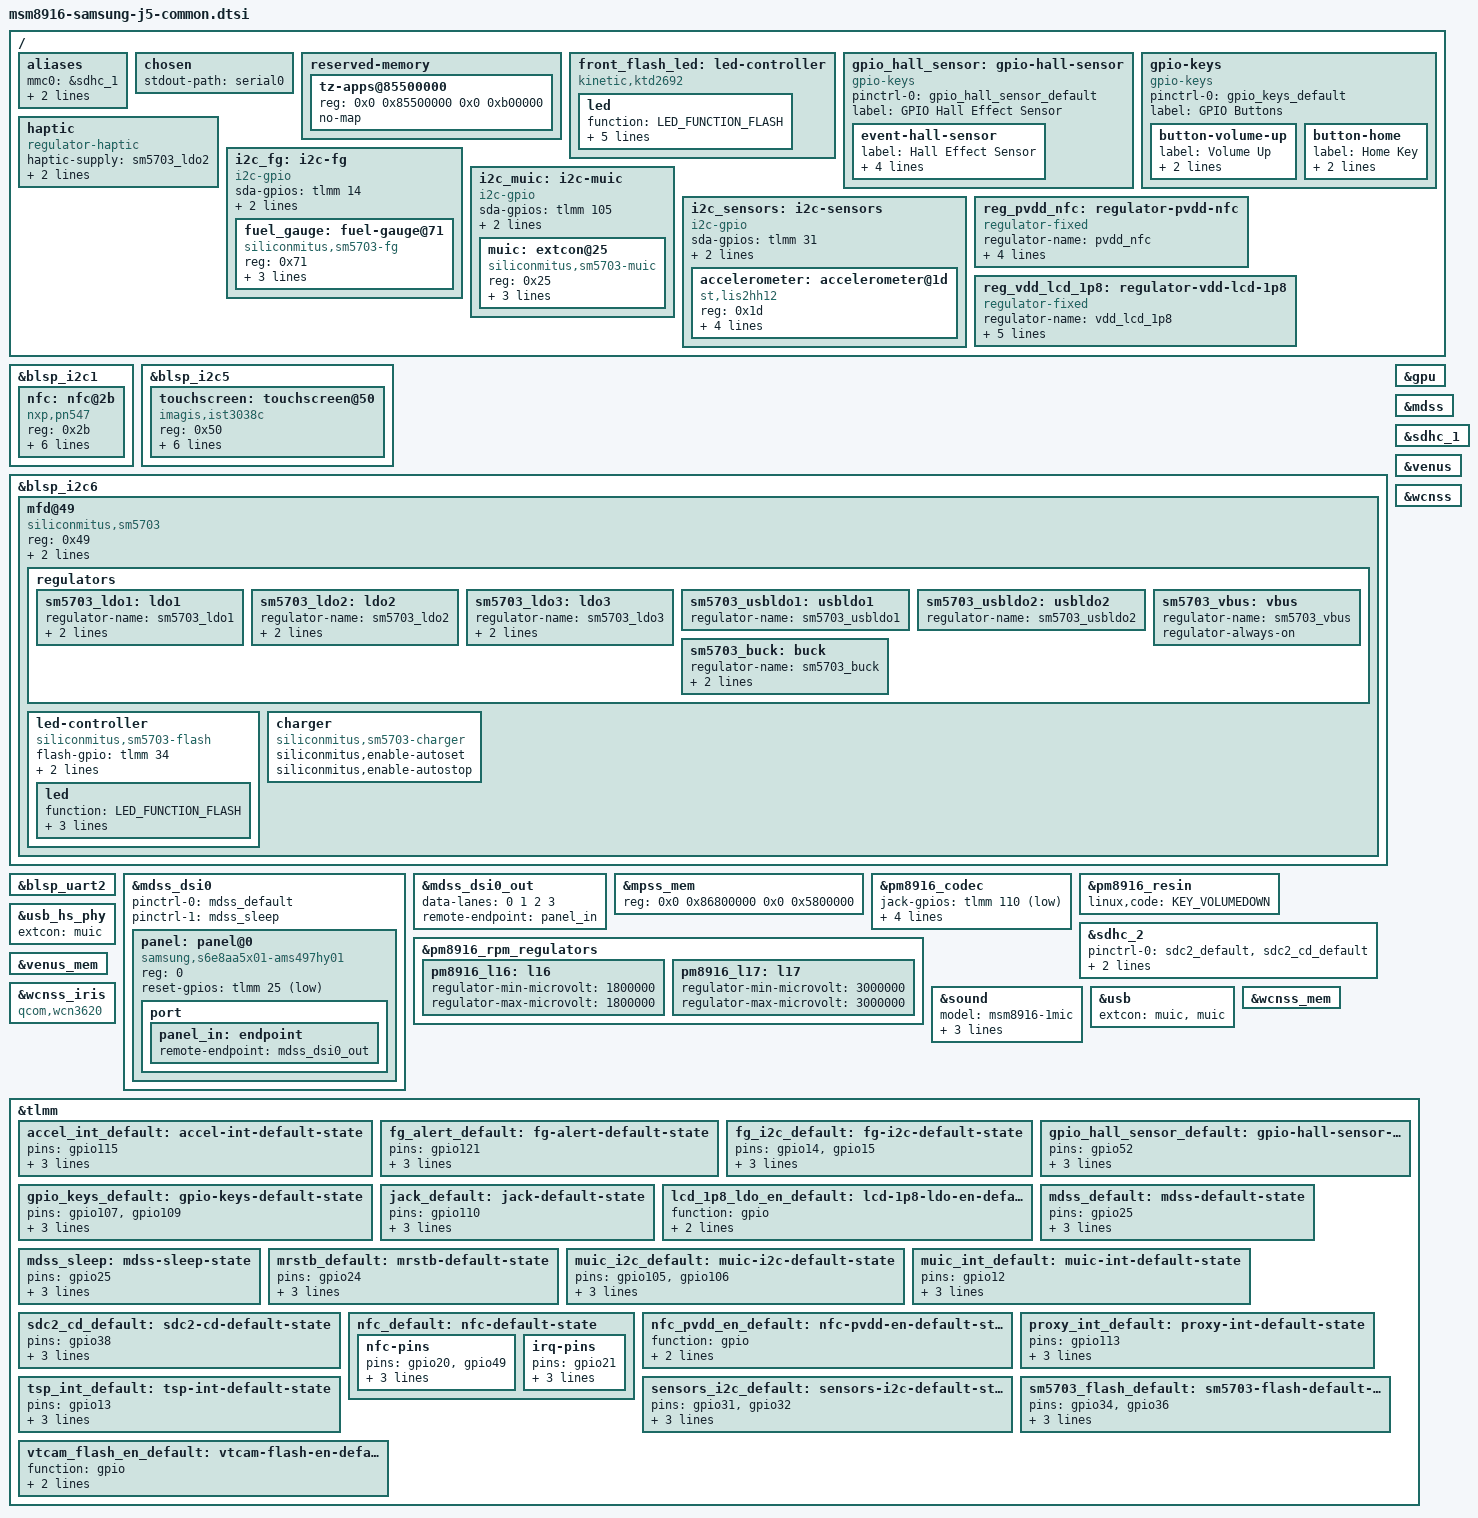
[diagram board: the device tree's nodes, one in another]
// SPDX-License-Identifier: GPL-2.0-only

#include "msm8916-pm8916.dtsi"
#include "msm8916-modem-qdsp6.dtsi"

#include <dt-bindings/gpio/gpio.h>
#include <dt-bindings/input/input.h>
#include <dt-bindings/interrupt-controller/irq.h>
#include <dt-bindings/leds/common.h>

/ {
	aliases {
		mmc0 = &sdhc_1; /* eMMC */
		mmc1 = &sdhc_2; /* SD card */
		serial0 = &blsp_uart2;
	};

	chosen {
		stdout-path = "serial0";
	};

	reserved-memory {
		/* Additional memory used by Samsung firmware modifications */
		tz-apps@85500000 {
			reg = <0x0 0x85500000 0x0 0xb00000>;
			no-map;
		};
	};

	front_flash_led: led-controller {
		compatible = "kinetic,ktd2692";

		led {
			function = LED_FUNCTION_FLASH;
			color = <LED_COLOR_ID_WHITE>;

			led-max-microamp = <300000>;
			flash-max-microamp = <1500000>;
			flash-max-timeout-us = <1835000>;

			pinctrl-0 = <&vtcam_flash_en_default>;
			pinctrl-names = "default";
		};
	};

	gpio_hall_sensor: gpio-hall-sensor {
		compatible = "gpio-keys";

		pinctrl-names = "default";
		pinctrl-0 = <&gpio_hall_sensor_default>;

		label = "GPIO Hall Effect Sensor";

		event-hall-sensor {
			label = "Hall Effect Sensor";
			gpios = <&tlmm 52 GPIO_ACTIVE_LOW>;
			linux,input-type = <EV_SW>;
			linux,code = <SW_LID>;
			linux,can-disable;
		};
	};

	gpio-keys {
		compatible = "gpio-keys";

		pinctrl-names = "default";
		pinctrl-0 = <&gpio_keys_default>;

		label = "GPIO Buttons";

		button-volume-up {
			label = "Volume Up";
			gpios = <&tlmm 107 GPIO_ACTIVE_LOW>;
			linux,code = <KEY_VOLUMEUP>;
		};

		button-home {
			label = "Home Key";
			gpios = <&tlmm 109 GPIO_ACTIVE_LOW>;
			linux,code = <KEY_HOMEPAGE>;
		};
	};

	haptic {
		compatible = "regulator-haptic";
		haptic-supply = <&sm5703_ldo2>;
		min-microvolt = <3300000>;
		max-microvolt = <3300000>;
	};

	i2c_fg: i2c-fg {
		compatible = "i2c-gpio";

		/* I2C4 */
		sda-gpios = <&tlmm 14 (GPIO_ACTIVE_HIGH|GPIO_OPEN_DRAIN)>;
		scl-gpios = <&tlmm 15 (GPIO_ACTIVE_HIGH|GPIO_OPEN_DRAIN)>;

		pinctrl-0 = <&fg_i2c_default>;
		pinctrl-names = "default";

		#address-cells = <1>;
		#size-cells = <0>;

		fuel_gauge: fuel-gauge@71 {
			compatible = "siliconmitus,sm5703-fg";
			reg = <0x71>;

			interrupt-parent = <&tlmm>;
			interrupts = <121 IRQ_TYPE_EDGE_FALLING>;

			pinctrl-0 = <&fg_alert_default>;
			pinctrl-names = "default";
		};
	};

	i2c_muic: i2c-muic {
		compatible = "i2c-gpio";
		sda-gpios = <&tlmm 105 (GPIO_ACTIVE_HIGH|GPIO_OPEN_DRAIN)>;
		scl-gpios = <&tlmm 106 (GPIO_ACTIVE_HIGH|GPIO_OPEN_DRAIN)>;

		pinctrl-names = "default";
		pinctrl-0 = <&muic_i2c_default>;

		#address-cells = <1>;
		#size-cells = <0>;

		muic: extcon@25 {
			compatible = "siliconmitus,sm5703-muic";
			reg = <0x25>;

			interrupt-parent = <&tlmm>;
			interrupts = <12 IRQ_TYPE_EDGE_FALLING>;

			pinctrl-names = "default";
			pinctrl-0 = <&muic_int_default>;
		};
	};

	i2c_sensors: i2c-sensors {
		compatible = "i2c-gpio";

		sda-gpios = <&tlmm 31 (GPIO_ACTIVE_HIGH|GPIO_OPEN_DRAIN)>;
		scl-gpios = <&tlmm 32 (GPIO_ACTIVE_HIGH|GPIO_OPEN_DRAIN)>;

		pinctrl-0 = <&sensors_i2c_default>;
		pinctrl-names = "default";

		#address-cells = <1>;
		#size-cells = <0>;

		accelerometer: accelerometer@1d {
			compatible = "st,lis2hh12";
			reg = <0x1d>;

			interrupts-extended = <&tlmm 115 IRQ_TYPE_LEVEL_HIGH>;

			pinctrl-0 = <&accel_int_default>;
			pinctrl-names = "default";

			st,drdy-int-pin = <1>;
		};
	};

	reg_pvdd_nfc: regulator-pvdd-nfc {
		compatible = "regulator-fixed";
		regulator-name = "pvdd_nfc";
		regulator-min-microvolt = <1800000>;
		regulator-max-microvolt = <1800000>;

		enable-active-high;

		pinctrl-0 = <&nfc_pvdd_en_default>;
		pinctrl-names = "default";
	};

	reg_vdd_lcd_1p8: regulator-vdd-lcd-1p8 {
		compatible = "regulator-fixed";
		regulator-name = "vdd_lcd_1p8";
		regulator-min-microvolt = <1800000>;
		regulator-max-microvolt = <1800000>;
		vin-supply = <&pm8916_s4>;

		enable-active-high;

		pinctrl-0 = <&lcd_1p8_ldo_en_default>;
		pinctrl-names = "default";
	};
};

&blsp_i2c1 {
	status = "okay";

	nfc: nfc@2b {
		compatible = "nxp,pn547", "nxp,nxp-nci-i2c";
		reg = <0x2b>;

		interrupt-parent = <&tlmm>;
		interrupts = <21 IRQ_TYPE_EDGE_RISING>;

		enable-gpios = <&tlmm 20 GPIO_ACTIVE_HIGH>;
		firmware-gpios = <&tlmm 49 GPIO_ACTIVE_HIGH>;

		pinctrl-0 = <&nfc_default>;
		pinctrl-names = "default";

		pvdd-supply = <&reg_pvdd_nfc>;
	};
};

&blsp_i2c5 {
	status = "okay";

	touchscreen: touchscreen@50 {
		compatible = "imagis,ist3038c";
		reg = <0x50>;

		interrupt-parent = <&tlmm>;
		interrupts = <13 IRQ_TYPE_EDGE_FALLING>;

		touchscreen-size-x = <720>;
		touchscreen-size-y = <1280>;

		vddio-supply = <&pm8916_l6>;

		pinctrl-0 = <&tsp_int_default>;
		pinctrl-names = "default";
	};
};

&blsp_i2c6 {
	status = "okay";

	mfd@49 {
		compatible = "siliconmitus,sm5703";
		reg = <0x49>;

		reset-gpio = <&tlmm 24 GPIO_ACTIVE_HIGH>;

		pinctrl-0 = <&mrstb_default>;
		pinctrl-names = "default";

		regulators {
			sm5703_ldo1: ldo1 {
				regulator-name = "sm5703_ldo1";
				regulator-min-microvolt = <2800000>;
				regulator-max-microvolt = <2800000>;
			};

			sm5703_ldo2: ldo2 {
				regulator-name = "sm5703_ldo2";
				regulator-min-microvolt = <1500000>;
				regulator-max-microvolt = <3300000>;
			};

			sm5703_ldo3: ldo3 {
				regulator-name = "sm5703_ldo3";
				regulator-min-microvolt = <3300000>;
				regulator-max-microvolt = <3300000>;
			};

			sm5703_usbldo1: usbldo1 {
				regulator-name = "sm5703_usbldo1";
			};

			sm5703_usbldo2: usbldo2 {
				regulator-name = "sm5703_usbldo2";
			};

			sm5703_vbus: vbus {
				regulator-name = "sm5703_vbus";
				/* HACK Keep it always on otherwise the USB
				 * network breaks */
				regulator-always-on;
			};

			sm5703_buck: buck {
				regulator-name = "sm5703_buck";
				regulator-min-microvolt = <1500000>;
				regulator-max-microvolt = <1500000>;
			};
		};

		led-controller {
			compatible = "siliconmitus,sm5703-flash";

			flash-gpio = <&tlmm 34 GPIO_ACTIVE_HIGH>;
			torch-gpio = <&tlmm 36 GPIO_ACTIVE_HIGH>;

			pinctrl-0 = <&sm5703_flash_default>;
			pinctrl-names = "default";

			led {
				function = LED_FUNCTION_FLASH;
				color = <LED_COLOR_ID_WHITE>;
				led-max-microamp = <170000>;
				flash-max-microamp = <1200000>;
			};
		};

		charger {
			compatible = "siliconmitus,sm5703-charger";
			siliconmitus,enable-autoset;
			siliconmitus,enable-autostop;
		};
	};
};

&blsp_uart2 {
	status = "okay";
};

&gpu {
	status = "okay";
};

&mdss {
	status = "okay";
};

&mdss_dsi0 {
	pinctrl-0 = <&mdss_default>;
	pinctrl-1 = <&mdss_sleep>;
	pinctrl-names = "default", "sleep";

	panel: panel@0 {
		reg = <0>;

		compatible = "samsung,s6e8aa5x01-ams497hy01";

		reset-gpios = <&tlmm 25 GPIO_ACTIVE_LOW>;

		port {
			panel_in: endpoint {
				remote-endpoint = <&mdss_dsi0_out>;
			};
		};
	};
};

&mdss_dsi0_out {
	data-lanes = <0 1 2 3>;
	remote-endpoint = <&panel_in>;
};

&mpss_mem {
	reg = <0x0 0x86800000 0x0 0x5800000>;
};

&pm8916_codec {
	jack-gpios = <&tlmm 110 GPIO_ACTIVE_LOW>;
	qcom,micbias-lvl = <2800>;
	qcom,mbhc-vthreshold-low = <75 150 237 450 500>;
	qcom,mbhc-vthreshold-high = <75 150 237 450 500>;

	pinctrl-0 = <&jack_default>;
	pinctrl-names = "default";
};

&pm8916_resin {
	status = "okay";
	linux,code = <KEY_VOLUMEDOWN>;
};

&pm8916_rpm_regulators {
	pm8916_l16: l16 {
		regulator-min-microvolt = <1800000>;
		regulator-max-microvolt = <1800000>;
	};

	pm8916_l17: l17 {
		regulator-min-microvolt = <3000000>;
		regulator-max-microvolt = <3000000>;
	};
};

&sdhc_1 {
	status = "okay";
};

&sdhc_2 {
	status = "okay";

	pinctrl-names = "default", "sleep";
	pinctrl-0 = <&sdc2_default &sdc2_cd_default>;
	pinctrl-1 = <&sdc2_sleep &sdc2_cd_default>;

	cd-gpios = <&tlmm 38 GPIO_ACTIVE_LOW>;
};

&sound {
	model = "msm8916-1mic";
	audio-routing =
		"AMIC1", "MIC BIAS External1",
		"AMIC2", "MIC BIAS Internal2",
		"AMIC3", "MIC BIAS External1";
};

&usb {
	extcon = <&muic>, <&muic>;
	//vbus-supply = <&sm5703_vbus>;
	status = "okay";
};

&usb_hs_phy {
	extcon = <&muic>;
};

&venus {
	status = "okay";
};

&venus_mem {
	status = "okay";
};

&wcnss {
	status = "okay";
};

&wcnss_iris {
	compatible = "qcom,wcn3620";
};

&wcnss_mem {
	status = "okay";
};

&tlmm {
	accel_int_default: accel-int-default-state {
		pins = "gpio115";
		function = "gpio";
		drive-strength = <2>;
		bias-disable;
	};

	fg_alert_default: fg-alert-default-state {
		pins = "gpio121";
		function = "gpio";
		drive-strength = <2>;
		bias-disable;
	};

	fg_i2c_default: fg-i2c-default-state {
		pins = "gpio14", "gpio15";
		function = "gpio";
		drive-strength = <2>;
		bias-disable;
	};

	gpio_hall_sensor_default: gpio-hall-sensor-default-state {
		pins = "gpio52";
		function = "gpio";

		drive-strength = <2>;
		bias-disable;
	};

	gpio_keys_default: gpio-keys-default-state {
		pins = "gpio107", "gpio109";
		function = "gpio";

		drive-strength = <2>;
		bias-pull-up;
	};

	jack_default: jack-default-state {
		pins = "gpio110";
		function = "gpio";
		drive-strength = <2>;
		bias-disable;
	};

	lcd_1p8_ldo_en_default: lcd-1p8-ldo-en-default-state {
		function = "gpio";

		drive-strength = <2>;
		bias-disable;
	};

	mdss_default: mdss-default-state {
		pins = "gpio25";
		function = "gpio";

		drive-strength = <8>;
		bias-disable;
	};

	mdss_sleep: mdss-sleep-state {
		pins = "gpio25";
		function = "gpio";

		drive-strength = <2>;
		bias-pull-down;
	};

	mrstb_default: mrstb-default-state {
		pins = "gpio24";
		function = "gpio";
		drive-strength = <2>;
		bias-disable;
	};

	muic_i2c_default: muic-i2c-default-state {
		pins = "gpio105", "gpio106";
		function = "gpio";

		drive-strength = <2>;
		bias-disable;
	};

	muic_int_default: muic-int-default-state {
		pins = "gpio12";
		function = "gpio";

		drive-strength = <2>;
		bias-disable;
	};

	sdc2_cd_default: sdc2-cd-default-state {
		pins = "gpio38";
		function = "gpio";

		drive-strength = <2>;
		bias-disable;
	};

	nfc_default: nfc-default-state {
		nfc-pins {
			pins = "gpio20", "gpio49";
			function = "gpio";
			drive-strength = <2>;
			bias-disable;
		};

		irq-pins {
			pins = "gpio21";
			function = "gpio";
			drive-strength = <2>;
			bias-pull-down;
		};
	};

	nfc_pvdd_en_default: nfc-pvdd-en-default-state {
		function = "gpio";

		drive-strength = <2>;
		bias-disable;
	};

	proxy_int_default: proxy-int-default-state {
		pins = "gpio113";
		function = "gpio";
		drive-strength = <2>;
		bias-disable;
	};

	sensors_i2c_default: sensors-i2c-default-state {
		pins = "gpio31", "gpio32";
		function = "gpio";
		drive-strength = <2>;
		bias-disable;
	};

	sm5703_flash_default: sm5703-flash-default-state {
		pins = "gpio34", "gpio36";
		function = "gpio";
		drive-strength = <2>;
		bias-disable;
	};

	tsp_int_default: tsp-int-default-state {
		pins = "gpio13";
		function = "gpio";

		drive-strength = <2>;
		bias-disable;
	};

	vtcam_flash_en_default: vtcam-flash-en-default-state {
		function = "gpio";
		drive-strength = <2>;
		bias-disable;
	};
};
